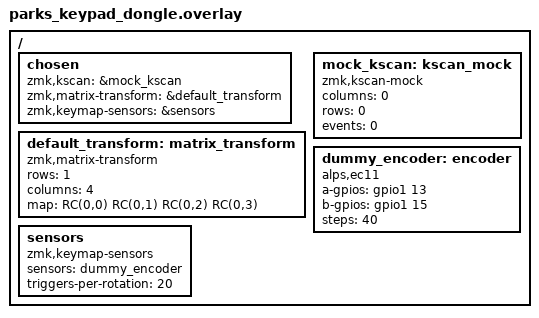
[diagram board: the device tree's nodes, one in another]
#include <dt-bindings/zmk/matrix_transform.h>

/ {
    chosen {
        zmk,kscan = &mock_kscan;
        zmk,matrix-transform = &default_transform;
        zmk,keymap-sensors = &sensors;
    };

    default_transform: matrix_transform {
        compatible = "zmk,matrix-transform";
        rows = <1>;
        columns = <4>;
        map = <
            RC(0,0) RC(0,1) RC(0,2) RC(0,3)
        >;
    };

    mock_kscan: kscan_mock {
        compatible = "zmk,kscan-mock";
        columns = <0>;
        rows = <0>;
        events = <0>;
    };

    dummy_encoder: encoder {
        compatible = "alps,ec11";
        a-gpios = <&gpio1 13 (GPIO_ACTIVE_HIGH | GPIO_PULL_UP)>;
        b-gpios = <&gpio1 15 (GPIO_ACTIVE_HIGH | GPIO_PULL_UP)>;
        steps = <40>;
        status = "okay";
    };

    sensors: sensors {
        compatible = "zmk,keymap-sensors";
        sensors = <&dummy_encoder>;
        triggers-per-rotation = <20>;
    };
};
